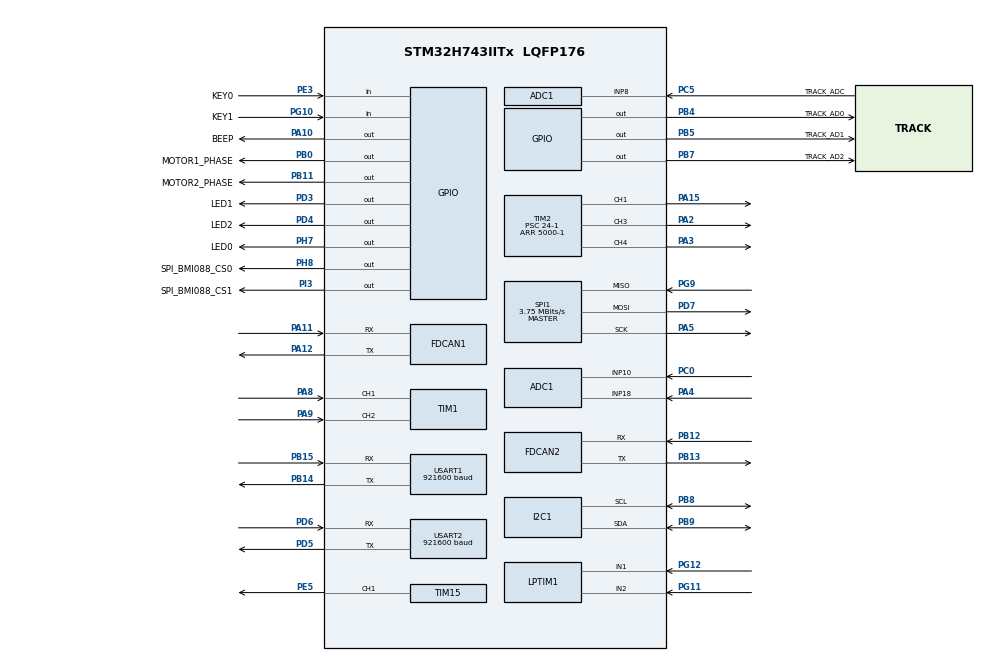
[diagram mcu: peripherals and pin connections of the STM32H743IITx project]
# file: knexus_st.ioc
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ADC1.Channel-0\#ChannelRegularConversion=ADC_CHANNEL_10
ADC1.Channel-1\#ChannelRegularConversion=ADC_CHANNEL_18
ADC1.ConversionDataManagement=ADC_CONVERSIONDATA_DMA_CIRCULAR
ADC1.EOCSelection=ADC_EOC_SEQ_CONV
ADC1.ExternalTrigConv=ADC_EXTERNALTRIG_T2_TRGO
ADC1.NbrOfConversion=2
ADC1.NbrOfConversionFlag=1
ADC1.OffsetNumber-0\#ChannelRegularConversion=ADC_OFFSET_NONE
ADC1.OffsetNumber-1\#ChannelRegularConversion=ADC_OFFSET_NONE
ADC1.OffsetSignedSaturation-0\#ChannelRegularConversion=DISABLE
ADC1.OffsetSignedSaturation-1\#ChannelRegularConversion=DISABLE
ADC1.Overrun=ADC_OVR_DATA_OVERWRITTEN
ADC1.Rank-0\#ChannelRegularConversion=1
ADC1.Rank-1\#ChannelRegularConversion=2
ADC1.SamplingTime-0\#ChannelRegularConversion=ADC_SAMPLETIME_64CYCLES_5
ADC1.SamplingTime-1\#ChannelRegularConversion=ADC_SAMPLETIME_64CYCLES_5
ADC1.master=1
ADC2.Channel-0\#ChannelRegularConversion=ADC_CHANNEL_8
ADC2.NbrOfConversionFlag=1
ADC2.OffsetNumber-0\#ChannelRegularConversion=ADC_OFFSET_NONE
ADC2.OffsetSignedSaturation-0\#ChannelRegularConversion=DISABLE
ADC2.Rank-0\#ChannelRegularConversion=1
ADC2.SamplingTime-0\#ChannelRegularConversion=ADC_SAMPLETIME_64CYCLES_5
CORTEX_M7.default_mode_Activation=1
Dma.ADC1.0.Direction=DMA_PERIPH_TO_MEMORY
Dma.ADC1.0.EventEnable=DISABLE
Dma.ADC1.0.FIFOMode=DMA_FIFOMODE_DISABLE
Dma.ADC1.0.Instance=DMA1_Stream0
Dma.ADC1.0.MemDataAlignment=DMA_MDATAALIGN_HALFWORD
Dma.ADC1.0.MemInc=DMA_MINC_ENABLE
Dma.ADC1.0.Mode=DMA_CIRCULAR
Dma.ADC1.0.PeriphDataAlignment=DMA_PDATAALIGN_HALFWORD
Dma.ADC1.0.PeriphInc=DMA_PINC_DISABLE
Dma.ADC1.0.Polarity=HAL_DMAMUX_REQ_GEN_RISING
Dma.ADC1.0.Priority=DMA_PRIORITY_VERY_HIGH
Dma.ADC1.0.RequestNumber=1
Dma.ADC1.0.SignalID=NONE
Dma.ADC1.0.SyncEnable=DISABLE
Dma.ADC1.0.SyncPolarity=HAL_DMAMUX_SYNC_NO_EVENT
Dma.ADC1.0.SyncRequestNumber=1
Dma.ADC1.0.SyncSignalID=NONE
Dma.Request0=ADC1
Dma.Request1=USART1_TX
Dma.USART1_TX.1.Direction=DMA_MEMORY_TO_PERIPH
Dma.USART1_TX.1.EventEnable=DISABLE
Dma.USART1_TX.1.FIFOMode=DMA_FIFOMODE_DISABLE
Dma.USART1_TX.1.Instance=DMA2_Stream7
Dma.USART1_TX.1.MemDataAlignment=DMA_MDATAALIGN_BYTE
Dma.USART1_TX.1.MemInc=DMA_MINC_ENABLE
Dma.USART1_TX.1.Mode=DMA_NORMAL
Dma.USART1_TX.1.PeriphDataAlignment=DMA_PDATAALIGN_BYTE
Dma.USART1_TX.1.PeriphInc=DMA_PINC_DISABLE
Dma.USART1_TX.1.Polarity=HAL_DMAMUX_REQ_GEN_RISING
Dma.USART1_TX.1.Priority=DMA_PRIORITY_MEDIUM
Dma.USART1_TX.1.RequestNumber=1
Dma.USART1_TX.1.SignalID=NONE
Dma.USART1_TX.1.SyncEnable=DISABLE
Dma.USART1_TX.1.SyncPolarity=HAL_DMAMUX_SYNC_NO_EVENT
Dma.USART1_TX.1.SyncRequestNumber=1
Dma.USART1_TX.1.SyncSignalID=NONE
FDCAN1.CalculateBaudRateNominal=1000000
FDCAN1.CalculateTimeBitNominal=1000
FDCAN1.CalculateTimeQuantumNominal=50.0
FDCAN1.NominalPrescaler=6
FDCAN1.NominalTimeSeg1=15
FDCAN1.NominalTimeSeg2=4
FDCAN1.RxFifo0ElmtsNbr=8
FDCAN1.StdFiltersNbr=1
FDCAN1.TxFifoQueueElmtsNbr=4
FDCAN2.CalculateBaudRateNominal=1000000
FDCAN2.CalculateTimeBitNominal=1000
FDCAN2.CalculateTimeQuantumNominal=25.0
FDCAN2.DataPrescaler=3
FDCAN2.DataSyncJumpWidth=10
FDCAN2.DataTimeSeg1=29
FDCAN2.DataTimeSeg2=10
FDCAN2.MessageRAMOffset=64
FDCAN2.NominalPrescaler=3
FDCAN2.NominalSyncJumpWidth=10
FDCAN2.NominalTimeSeg1=29
FDCAN2.NominalTimeSeg2=10
FDCAN2.RxFifo0ElmtsNbr=4
FDCAN2.StdFiltersNbr=1
FDCAN2.TxFifoQueueElmtsNbr=4
FREERTOS.Tasks01=defaultTask,24,128,StartDefaultTask,Default,NULL,Dynamic,NULL,NULL
FREERTOS.configENABLE_FPU=1
FREERTOS.configUSE_NEWLIB_REENTRANT=1
I2C1.Timing=0x30701C2D
Mcu.Family=STM32H7
Mcu.Name=STM32H743IITx
Mcu.Package=LQFP176
NVIC.DMA1_Stream0_IRQn=true\:5\:0\:false\:false\:true\:true\:false\:true\:true
NVIC.DMA2_Stream7_IRQn=true\:5\:0\:false\:false\:true\:true\:false\:true\:true
NVIC.FDCAN1_IT0_IRQn=true\:5\:0\:false\:false\:true\:true\:true\:true\:true
NVIC.FDCAN2_IT0_IRQn=true\:5\:0\:false\:false\:true\:true\:true\:true\:true
NVIC.LPTIM1_IRQn=true\:5\:0\:false\:false\:true\:true\:true\:true\:true
NVIC.PriorityGroup=NVIC_PRIORITYGROUP_4
NVIC.TIM17_IRQn=true\:15\:0\:false\:false\:true\:false\:false\:true\:true
NVIC.TIM1_UP_IRQn=true\:5\:0\:false\:false\:true\:true\:true\:true\:true
NVIC.TimeBase=TIM17_IRQn
NVIC.TimeBaseIP=TIM17
NVIC.USART1_IRQn=true\:5\:0\:false\:false\:true\:true\:true\:true\:true
NVIC.USART2_IRQn=true\:5\:0\:false\:false\:true\:true\:true\:true\:true
PA10.GPIO_Label=BEEP
PA10.Signal=GPIO_Output
PA11.Mode=FDCAN_Activate
PA11.Signal=FDCAN1_RX
PA12.Mode=FDCAN_Activate
PA12.Signal=FDCAN1_TX
PA13\ (JTMS/SWDIO).Mode=Serial_Wire
PA13\ (JTMS/SWDIO).Signal=DEBUG_JTMS-SWDIO
PA13\ (JTMS/SWDIO).Stacked=true
PA14\ (JTCK/SWCLK).Mode=Serial_Wire
PA14\ (JTCK/SWCLK).Signal=DEBUG_JTCK-SWCLK
PA14\ (JTCK/SWCLK).Stacked=true
PA15\ (JTDI).Signal=S_TIM2_CH1_ETR
PA15\ (JTDI).Stacked=true
PA2.Signal=S_TIM2_CH3
PA3.Signal=S_TIM2_CH4
PA4.Signal=ADCx_INP18
PA5.GPIO_Speed=GPIO_SPEED_FREQ_HIGH
PA5.Mode=Full_Duplex_Master
PA5.Signal=SPI1_SCK
PA5.Stacked=true
PA8.Signal=S_TIM1_CH1
PA8.Stacked=true
PA9.Signal=S_TIM1_CH2
PA9.Stacked=true
PB0.GPIO_Label=MOTOR1_PHASE
PB0.Signal=GPIO_Output
PB11.GPIO_Label=MOTOR2_PHASE
PB11.Signal=GPIO_Output
PB12.GPIO_Speed=GPIO_SPEED_FREQ_VERY_HIGH
PB12.Mode=FDCAN_Activate
PB12.Signal=FDCAN2_RX
PB13.GPIO_Speed=GPIO_SPEED_FREQ_VERY_HIGH
PB13.Mode=FDCAN_Activate
PB13.Signal=FDCAN2_TX
PB14.Mode=Asynchronous
PB14.Signal=USART1_TX
PB14.Stacked=true
PB15.Mode=Asynchronous
PB15.Signal=USART1_RX
PB15.Stacked=true
PB4\ (NJTRST).GPIO_Label=TRACK_AD0
PB4\ (NJTRST).Signal=GPIO_Output
PB5.GPIO_Label=TRACK_AD1
PB5.Signal=GPIO_Output
PB7.GPIO_Label=TRACK_AD2
PB7.Signal=GPIO_Output
PB8.Mode=I2C
PB8.Signal=I2C1_SCL
PB9.Mode=I2C
PB9.Signal=I2C1_SDA
PC0.Signal=ADCx_INP10
PC5.GPIO_Label=TRACK_ADC
PC5.Signal=ADCx_INP8
PD3.GPIO_Label=LED1
PD3.Signal=GPIO_Output
PD4.GPIO_Label=LED2
PD4.Signal=GPIO_Output
PD5.Mode=Asynchronous
PD5.Signal=USART2_TX
PD5.Stacked=true
PD6.Mode=Asynchronous
PD6.Signal=USART2_RX
PD6.Stacked=true
PD7.GPIO_Speed=GPIO_SPEED_FREQ_HIGH
PD7.Mode=Full_Duplex_Master
PD7.Signal=SPI1_MOSI
PD7.Stacked=true
PE3.GPIO_Label=KEY0
PE3.GPIO_PuPd=GPIO_PULLDOWN
PE3.Signal=GPIO_Input
PE5.Signal=S_TIM15_CH1
PE5.Stacked=true
PG10.GPIO_Label=KEY1
PG10.GPIO_PuPd=GPIO_PULLDOWN
PG10.Signal=GPIO_Input
PG11.Mode=Encoder_mode_occur1
PG11.Signal=LPTIM1_IN2
PG11.Stacked=true
PG12.Mode=Encoder_mode_occur1
PG12.Signal=LPTIM1_IN1
PG12.Stacked=true
PG9.GPIO_Speed=GPIO_SPEED_FREQ_HIGH
PG9.Mode=Full_Duplex_Master
PG9.Signal=SPI1_MISO
PG9.Stacked=true
PH0-OSC_IN\ (PH0).Mode=HSE-External-Oscillator
PH0-OSC_IN\ (PH0).Signal=RCC_OSC_IN
PH1-OSC_OUT\ (PH1).Mode=HSE-External-Oscillator
PH1-OSC_OUT\ (PH1).Signal=RCC_OSC_OUT
PH7.GPIO_Label=LED0
PH7.GPIO_Speed=GPIO_SPEED_FREQ_HIGH
PH7.PinState=GPIO_PIN_RESET
PH7.Signal=GPIO_Output
PH7.Stacked=true
PH8.GPIO_Label=SPI_BMI088_CS0
PH8.GPIO_Speed=GPIO_SPEED_FREQ_HIGH
PH8.PinState=GPIO_PIN_SET
PH8.Signal=GPIO_Output
PH8.Stacked=true
PI3.GPIO_Label=SPI_BMI088_CS1
PI3.GPIO_Speed=GPIO_SPEED_FREQ_HIGH
PI3.PinState=GPIO_PIN_SET
PI3.Signal=GPIO_Output
PI3.Stacked=true
ProjectManager.HeapSize=0x200
ProjectManager.StackSize=0x400
ProjectManager.TargetToolchain=STM32CubeIDE
RCC.ADCFreq_Value=83333333.33333334
RCC.APB1Freq_Value=120000000
RCC.APB2Freq_Value=120000000
RCC.APB3Freq_Value=120000000
RCC.APB4Freq_Value=120000000
RCC.CortexFreq_Value=480000000
RCC.D1PPRE=RCC_APB3_DIV2
RCC.D2PPRE1=RCC_APB1_DIV2
RCC.D2PPRE2=RCC_APB2_DIV2
RCC.D3PPRE=RCC_APB4_DIV2
RCC.DIVM1=5
RCC.DIVM2=15
RCC.DIVN1=192
RCC.DIVN2=100
RCC.DIVQ1=8
RCC.HCLKFreq_Value=240000000
RCC.HPRE=RCC_HCLK_DIV2
RCC.PLLFRACN=0
RCC.PLLSourceVirtual=RCC_PLLSOURCE_HSE
RCC.SYSCLKFreq_VALUE=480000000
RCC.SYSCLKSource=RCC_SYSCLKSOURCE_PLLCLK
RCC.USBFreq_Value=120000000
SH.ADCx_INP10.0=ADC1_INP10,IN10-Single-Ended
SH.ADCx_INP18.0=ADC1_INP18,IN18-Single-Ended
SH.ADCx_INP8.0=ADC1_INP8,IN8-Single-Ended
SH.ADCx_INP8.1=ADC2_INP8,IN8-Single-Ended
SH.S_TIM15_CH1.0=TIM15_CH1,PWM Generation1 CH1
SH.S_TIM1_CH1.0=TIM1_CH1,Encoder_Interface
SH.S_TIM1_CH2.0=TIM1_CH2,Encoder_Interface
SH.S_TIM2_CH1_ETR.0=TIM2_CH1,PWM Generation1 CH1
SH.S_TIM2_CH3.0=TIM2_CH3,PWM Generation3 CH3
SH.S_TIM2_CH4.0=TIM2_CH4,Output Compare4 CH4
SPI1.BaudRatePrescaler=SPI_BAUDRATEPRESCALER_32
SPI1.CalculateBaudRate=3.75 MBits/s
SPI1.DataSize=SPI_DATASIZE_8BIT
SPI1.Direction=SPI_DIRECTION_2LINES
SPI1.Mode=SPI_MODE_MASTER
SPI1.VirtualType=VM_MASTER
STMicroelectronics.X-CUBE-ALGOBUILD.1.5.0.LibraryCcDSPOoLibraryJjDSPOoLibrary=true
TIM1.EncoderMode=TIM_ENCODERMODE_TI12
TIM15.Channel-PWM\ Generation1\ CH1=TIM_CHANNEL_1
TIM2.Channel-Output\ Compare4\ CH4=TIM_CHANNEL_4
TIM2.Channel-PWM\ Generation1\ CH1=TIM_CHANNEL_1
TIM2.Channel-PWM\ Generation3\ CH3=TIM_CHANNEL_3
TIM2.CounterMode=TIM_COUNTERMODE_CENTERALIGNED1
TIM2.OCMode_4=TIM_OCMODE_TOGGLE
TIM2.Period=5000-1
TIM2.Prescaler=24-1
TIM2.Pulse-Output\ Compare4\ CH4=250
TIM2.TIM_MasterOutputTrigger=TIM_TRGO_OC4REF
TIM2.TIM_MasterSlaveMode=TIM_MASTERSLAVEMODE_ENABLE
USART1.BaudRate=921600
USART1.VirtualMode-Asynchronous=VM_ASYNC
USART2.BaudRate=921600
USART2.VirtualMode-Asynchronous=VM_ASYNC
VP_FREERTOS_VS_CMSIS_V2.Mode=CMSIS_V2
VP_MEMORYMAP_VS_MEMORYMAP.Mode=CurAppReg
VP_STMicroelectronics.X-CUBE-ALGOBUILD_VS_DSPOoLibraryJjLibrary_1.5.0_1.5.0.Mode=DSPOoLibraryJjLibrary
VP_SYS_VS_tim17.Mode=TIM17
board=custom

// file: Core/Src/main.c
/* USER CODE BEGIN Header */
/**
  ******************************************************************************
  * @file           : main.c
  * @brief          : Main program body
  ******************************************************************************
  */
/* USER CODE END Header */
#include "main.h"
#include "FreeRTOS.h"
#include "cmsis_os2.h"
#include "adc.h"
#include "dma.h"
#include "fdcan.h"
#include "i2c.h"
#include "lptim.h"
#include "spi.h"
#include "tim.h"
#include "usart.h"
#include "gpio.h"

void SystemClock_Config(void);
void PeriphCommonClock_Config(void);
static void MPU_Config(void);
void MX_FREERTOS_Init(void);

int main(void)
{

  /* MPU Configuration--------------------------------------------------------*/
  MPU_Config();

  /* MCU Configuration--------------------------------------------------------*/

  /* Reset of all peripherals, Initializes the Flash interface and the Systick. */
  HAL_Init();

  /* Configure the system clock */
  SystemClock_Config();

  /* Configure the peripherals common clocks */
  PeriphCommonClock_Config();

  /* Initialize all configured peripherals */
  MX_GPIO_Init();
  MX_DMA_Init();
  MX_USART1_UART_Init();
  MX_USART2_UART_Init();
  MX_SPI1_Init();
  MX_TIM15_Init();
  MX_TIM2_Init();
  MX_LPTIM1_Init();
  MX_TIM1_Init();
  MX_ADC1_Init();
  MX_ADC2_Init();
  MX_FDCAN1_Init();
  MX_FDCAN2_Init();
  MX_I2C1_Init();
  /* USER CODE BEGIN 2 */
  /* Driver inits moved to knx_app_init() via board/app layers */
  /* USER CODE END 2 */

  /* Init scheduler */
  osKernelInitialize();  /* Call init function for freertos objects (in cmsis_os2.c) */
  MX_FREERTOS_Init();

  /* Start scheduler */
  osKernelStart();

  /* We should never get here as control is now taken by the scheduler */

  /* Infinite loop */
  while (1)
  {

  }
}

void SystemClock_Config(void)
{
  RCC_OscInitTypeDef RCC_OscInitStruct = {0};
  RCC_ClkInitTypeDef RCC_ClkInitStruct = {0};

  /** Supply configuration update enable
  */
  HAL_PWREx_ConfigSupply(PWR_LDO_SUPPLY);

  /** Configure the main internal regulator output voltage
  */
  __HAL_PWR_VOLTAGESCALING_CONFIG(PWR_REGULATOR_VOLTAGE_SCALE0);

  while(!__HAL_PWR_GET_FLAG(PWR_FLAG_VOSRDY)) {}

  /** Initializes the RCC Oscillators according to the specified parameters
  * in the RCC_OscInitTypeDef structure.
  */
  RCC_OscInitStruct.OscillatorType = RCC_OSCILLATORTYPE_HSE;
  RCC_OscInitStruct.HSEState = RCC_HSE_ON;
  RCC_OscInitStruct.PLL.PLLState = RCC_PLL_ON;
  RCC_OscInitStruct.PLL.PLLSource = RCC_PLLSOURCE_HSE;
  RCC_OscInitStruct.PLL.PLLM = 5;
  RCC_OscInitStruct.PLL.PLLN = 192;
  RCC_OscInitStruct.PLL.PLLP = 2;
  RCC_OscInitStruct.PLL.PLLQ = 8;
  RCC_OscInitStruct.PLL.PLLR = 2;
  RCC_OscInitStruct.PLL.PLLRGE = RCC_PLL1VCIRANGE_2;
  RCC_OscInitStruct.PLL.PLLVCOSEL = RCC_PLL1VCOWIDE;
  RCC_OscInitStruct.PLL.PLLFRACN = 0;
  if (HAL_RCC_OscConfig(&RCC_OscInitStruct) != HAL_OK)
  {
    Error_Handler();
  }

  /** Initializes the CPU, AHB and APB buses clocks
  */
  RCC_ClkInitStruct.ClockType = RCC_CLOCKTYPE_HCLK|RCC_CLOCKTYPE_SYSCLK
                              |RCC_CLOCKTYPE_PCLK1|RCC_CLOCKTYPE_PCLK2
                              |RCC_CLOCKTYPE_D3PCLK1|RCC_CLOCKTYPE_D1PCLK1;
  RCC_ClkInitStruct.SYSCLKSource = RCC_SYSCLKSOURCE_PLLCLK;
  RCC_ClkInitStruct.SYSCLKDivider = RCC_SYSCLK_DIV1;
  RCC_ClkInitStruct.AHBCLKDivider = RCC_HCLK_DIV2;
  RCC_ClkInitStruct.APB3CLKDivider = RCC_APB3_DIV2;
  RCC_ClkInitStruct.APB1CLKDivider = RCC_APB1_DIV2;
  RCC_ClkInitStruct.APB2CLKDivider = RCC_APB2_DIV2;
  RCC_ClkInitStruct.APB4CLKDivider = RCC_APB4_DIV2;

  if (HAL_RCC_ClockConfig(&RCC_ClkInitStruct, FLASH_LATENCY_4) != HAL_OK)
  {
    Error_Handler();
  }
}

void PeriphCommonClock_Config(void)
{
  RCC_PeriphCLKInitTypeDef PeriphClkInitStruct = {0};

  /** Initializes the peripherals clock
  */
  PeriphClkInitStruct.PeriphClockSelection = RCC_PERIPHCLK_ADC;
  PeriphClkInitStruct.PLL2.PLL2M = 15;
  PeriphClkInitStruct.PLL2.PLL2N = 100;
  PeriphClkInitStruct.PLL2.PLL2P = 2;
  PeriphClkInitStruct.PLL2.PLL2Q = 2;
  PeriphClkInitStruct.PLL2.PLL2R = 2;
  PeriphClkInitStruct.PLL2.PLL2RGE = RCC_PLL2VCIRANGE_0;
  PeriphClkInitStruct.PLL2.PLL2VCOSEL = RCC_PLL2VCOMEDIUM;
  PeriphClkInitStruct.PLL2.PLL2FRACN = 0;
  PeriphClkInitStruct.AdcClockSelection = RCC_ADCCLKSOURCE_PLL2;
  if (HAL_RCCEx_PeriphCLKConfig(&PeriphClkInitStruct) != HAL_OK)
  {
    Error_Handler();
  }
}

 /* MPU Configuration */

void MPU_Config(void)
{
  MPU_Region_InitTypeDef MPU_InitStruct = {0};

  /* Disables the MPU */
  HAL_MPU_Disable();

  /** Initializes and configures the Region and the memory to be protected
  */
  MPU_InitStruct.Enable = MPU_REGION_ENABLE;
  MPU_InitStruct.Number = MPU_REGION_NUMBER0;
  MPU_InitStruct.BaseAddress = 0x0;
  MPU_InitStruct.Size = MPU_REGION_SIZE_4GB;
  MPU_InitStruct.SubRegionDisable = 0x87;
  MPU_InitStruct.TypeExtField = MPU_TEX_LEVEL0;
  MPU_InitStruct.AccessPermission = MPU_REGION_NO_ACCESS;
  MPU_InitStruct.DisableExec = MPU_INSTRUCTION_ACCESS_DISABLE;
  MPU_InitStruct.IsShareable = MPU_ACCESS_SHAREABLE;
  MPU_InitStruct.IsCacheable = MPU_ACCESS_NOT_CACHEABLE;
  MPU_InitStruct.IsBufferable = MPU_ACCESS_NOT_BUFFERABLE;

  HAL_MPU_ConfigRegion(&MPU_InitStruct);
  /* Enables the MPU */
  HAL_MPU_Enable(MPU_PRIVILEGED_DEFAULT);

}

void HAL_TIM_PeriodElapsedCallback(TIM_HandleTypeDef *htim)
{
  if (htim->Instance == TIM17)
  {
    HAL_IncTick();
  }
}

void Error_Handler(void)
{
  __disable_irq();
  while (1)
  {
  }
}

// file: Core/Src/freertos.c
/* USER CODE BEGIN Header */
/**
  ******************************************************************************
  * File Name          : freertos.c
  * Description        : Code for freertos applications
  ******************************************************************************
  * @attention
  *
  * Copyright (c) 2026 STMicroelectronics.
  * All rights reserved.
  *
  * This software is licensed under terms that can be found in the LICENSE file
  * in the root directory of this software component.
  * If no LICENSE file comes with this software, it is provided AS-IS.
  *
  ******************************************************************************
  */
/* USER CODE END Header */

#include "FreeRTOS.h"
#include "task.h"
#include "main.h"
#include "FreeRTOS.h"
#include "cmsis_os2.h"

/* USER CODE BEGIN Includes */
#include "knx_tasks.h"
#include "stm32h7xx.h"
#include "knx_sys.h"
#include "knx_safety.h"

/* USER CODE END Includes */

/* Definitions for defaultTask */
osThreadId_t defaultTaskHandle;
const osThreadAttr_t defaultTask_attributes = {
  .name = "defaultTask",
  .stack_size = 128 * 4,
  .priority = (osPriority_t) osPriorityNormal,
};

void StartDefaultTask(void *argument);

void MX_FREERTOS_Init(void); /* (MISRA C 2004 rule 8.1) */

void MX_FREERTOS_Init(void) {

  /* Create the thread(s) */
  /* creation of defaultTask */
  defaultTaskHandle = osThreadNew(StartDefaultTask, NULL, &defaultTask_attributes);

  /* USER CODE BEGIN RTOS_THREADS */
  knx_tasks_init();
  /* USER CODE END RTOS_THREADS */

}

void StartDefaultTask(void *argument)
{
  /* USER CODE BEGIN StartDefaultTask */
  (void)argument;
  /* CubeMX requires a default-task entry, but contest_2026 owns its complete
   * task set.  Delete this otherwise-empty 1 kHz task after the scheduler
   * starts so it does not add needless context switches. */
  osThreadExit();
  /* USER CODE END StartDefaultTask */
}

/* USER CODE BEGIN Application */

/* 栈溢出钩子: FreeRTOS configCHECK_FOR_STACK_OVERFLOW=2 时由内核调用 */
void vApplicationStackOverflowHook(TaskHandle_t xTask, char *pcTaskName)
{
    (void)xTask;
    (void)pcTaskName;
    /* 记录故障(使用WATCHDOG故障码,无专用STACK_OVERFLOW码) */
    knx_sys_report_fault(KNX_FAULT_WATCHDOG);
    /* 栈溢出是致命错误,直接复位系统 */
    NVIC_SystemReset();
}

/* malloc失败钩子: FreeRTOS configUSE_MALLOC_FAILED_HOOK=1 时由内核调用 */
void vApplicationMallocFailedHook(void)
{
    /* 记录故障 */
    knx_sys_report_fault(KNX_FAULT_WATCHDOG);
    /* 堆耗尽是致命错误,直接复位系统 */
    NVIC_SystemReset();
}

/* USER CODE END Application */
